AUTOSAR XML (schema 00050)
standard types defined: Boolean, Float
package /ARRoot
  5 x trigger interface:
    ExternalTriggerForRainWipe
    ExternalTriggerForRearWipe
    ExternalTriggerForSingleWipe
    ExternalTriggerForSpeedOfWiper
    ExternalTriggerForWashAndWipe
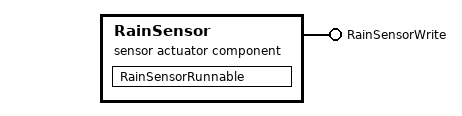
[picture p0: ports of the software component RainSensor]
  sensor actuator sw component type RainSensor
    provide port RainSensorWrite
    behavior RainSensorIB
      runnable RainSensorRunnable: variable-access=accessed-variable=/ARRoot/RainSensorSRIF/
  swc implementation RainSensorImp: programming-language=C, behavior=RainSensorIB
  sender receiver interface RainSensorSRIF: data-elements=variable-data-prototype=type=Boolean
  client server interface RainWipeCSIF: client-server-operation=arguments=argument-data-prototype={type=Boolean, direction=OUT}
  swc implementation RainWipeImp: programming-language=C, behavior=RainWiperIB
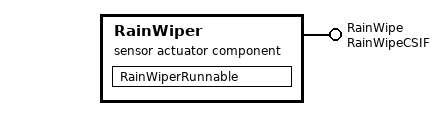
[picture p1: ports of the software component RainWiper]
  sensor actuator sw component type RainWiper
    provide port RainWipe: provided-interface=RainWipeCSIF
    behavior RainWiperIB
      runnable RainWiperRunnable: external-triggering-point=RainWipe.
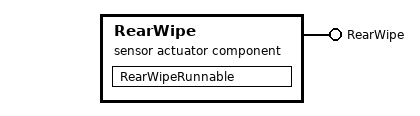
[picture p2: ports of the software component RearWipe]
  sensor actuator sw component type RearWipe
    provide port RearWipe
    behavior RearWipeIB
      runnable RearWipeRunnable: external-triggering-point=RearWipe.
  client server interface RearWipeCSIF: client-server-operation=arguments=argument-data-prototype={type=Boolean, direction=OUT}
  swc implementation RearWipeImp: programming-language=C, behavior=RearWipeIB
  client server interface SingleWipeCSIF: client-server-operation=arguments=argument-data-prototype={type=Boolean, direction=OUT}
  swc implementation SingleWipeImp: programming-language=C, behavior=SingleWiperIB
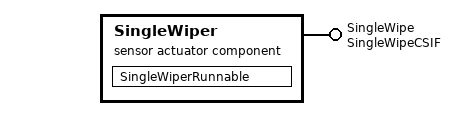
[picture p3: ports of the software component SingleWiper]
  sensor actuator sw component type SingleWiper
    provide port SingleWipe: provided-interface=SingleWipeCSIF
    behavior SingleWiperIB
      runnable SingleWiperRunnable: external-triggering-point=SingleWipe.
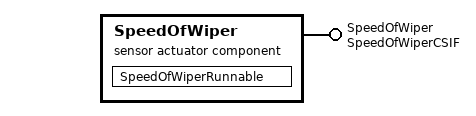
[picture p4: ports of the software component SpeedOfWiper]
  sensor actuator sw component type SpeedOfWiper
    provide port SpeedOfWiper: provided-interface=SpeedOfWiperCSIF
    behavior SpeedOfWiperIB
      runnable SpeedOfWiperRunnable: external-triggering-point=SpeedOfWiper.
  client server interface SpeedOfWiperCSIF: client-server-operation=arguments=argument-data-prototype={type=Float, direction=OUT}
  swc implementation SpeedOfWiperImp: programming-language=C, behavior=SpeedOfWiperIB
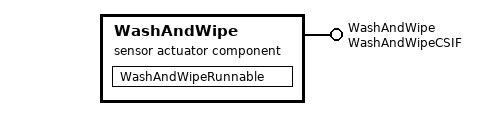
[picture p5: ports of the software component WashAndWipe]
  sensor actuator sw component type WashAndWipe
    provide port WashAndWipe: provided-interface=WashAndWipeCSIF
    behavior WashAndWipeIB
      runnable WashAndWipeRunnable: external-triggering-point=WashAndWipe.
  client server interface WashAndWipeCSIF: client-server-operation=arguments=argument-data-prototype={type=Boolean, direction=OUT}
  swc implementation WashAndWipeImp: programming-language=C, behavior=WashAndWipeIB
  swc implementation WiperControllerImp: programming-language=C, behavior=WiperContolIB
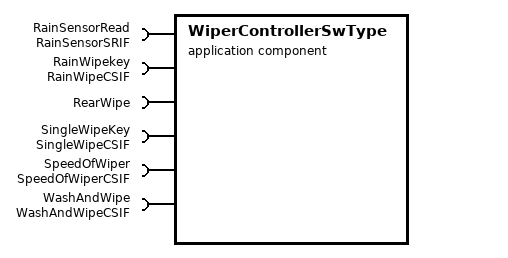
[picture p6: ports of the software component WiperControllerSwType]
  application sw component type WiperControllerSwType
    6 x require port:
      RainSensorRead: required-interface=RainSensorSRIF
      RainWipekey: required-interface=RainWipeCSIF
      RearWipe
      SingleWipeKey: required-interface=SingleWipeCSIF
      SpeedOfWiper: required-interface=SpeedOfWiperCSIF
      WashAndWipe: required-interface=WashAndWipeCSIF
    behavior WiperContolIB
      6 x runnable:
        RainSensor: variable-access=accessed-variable=/ARRoot/RainSensorSRIF/
        RainWipe: synchronous-server-call-point=RainWipekey.
        RearWipe: synchronous-server-call-point=RearWipe.
        SingleWipe: synchronous-server-call-point=SingleWipeKey.
        SpeedOfWiper: synchronous-server-call-point=SpeedOfWiper.
        WashAndWipe: synchronous-server-call-point=WashAndWipe.
